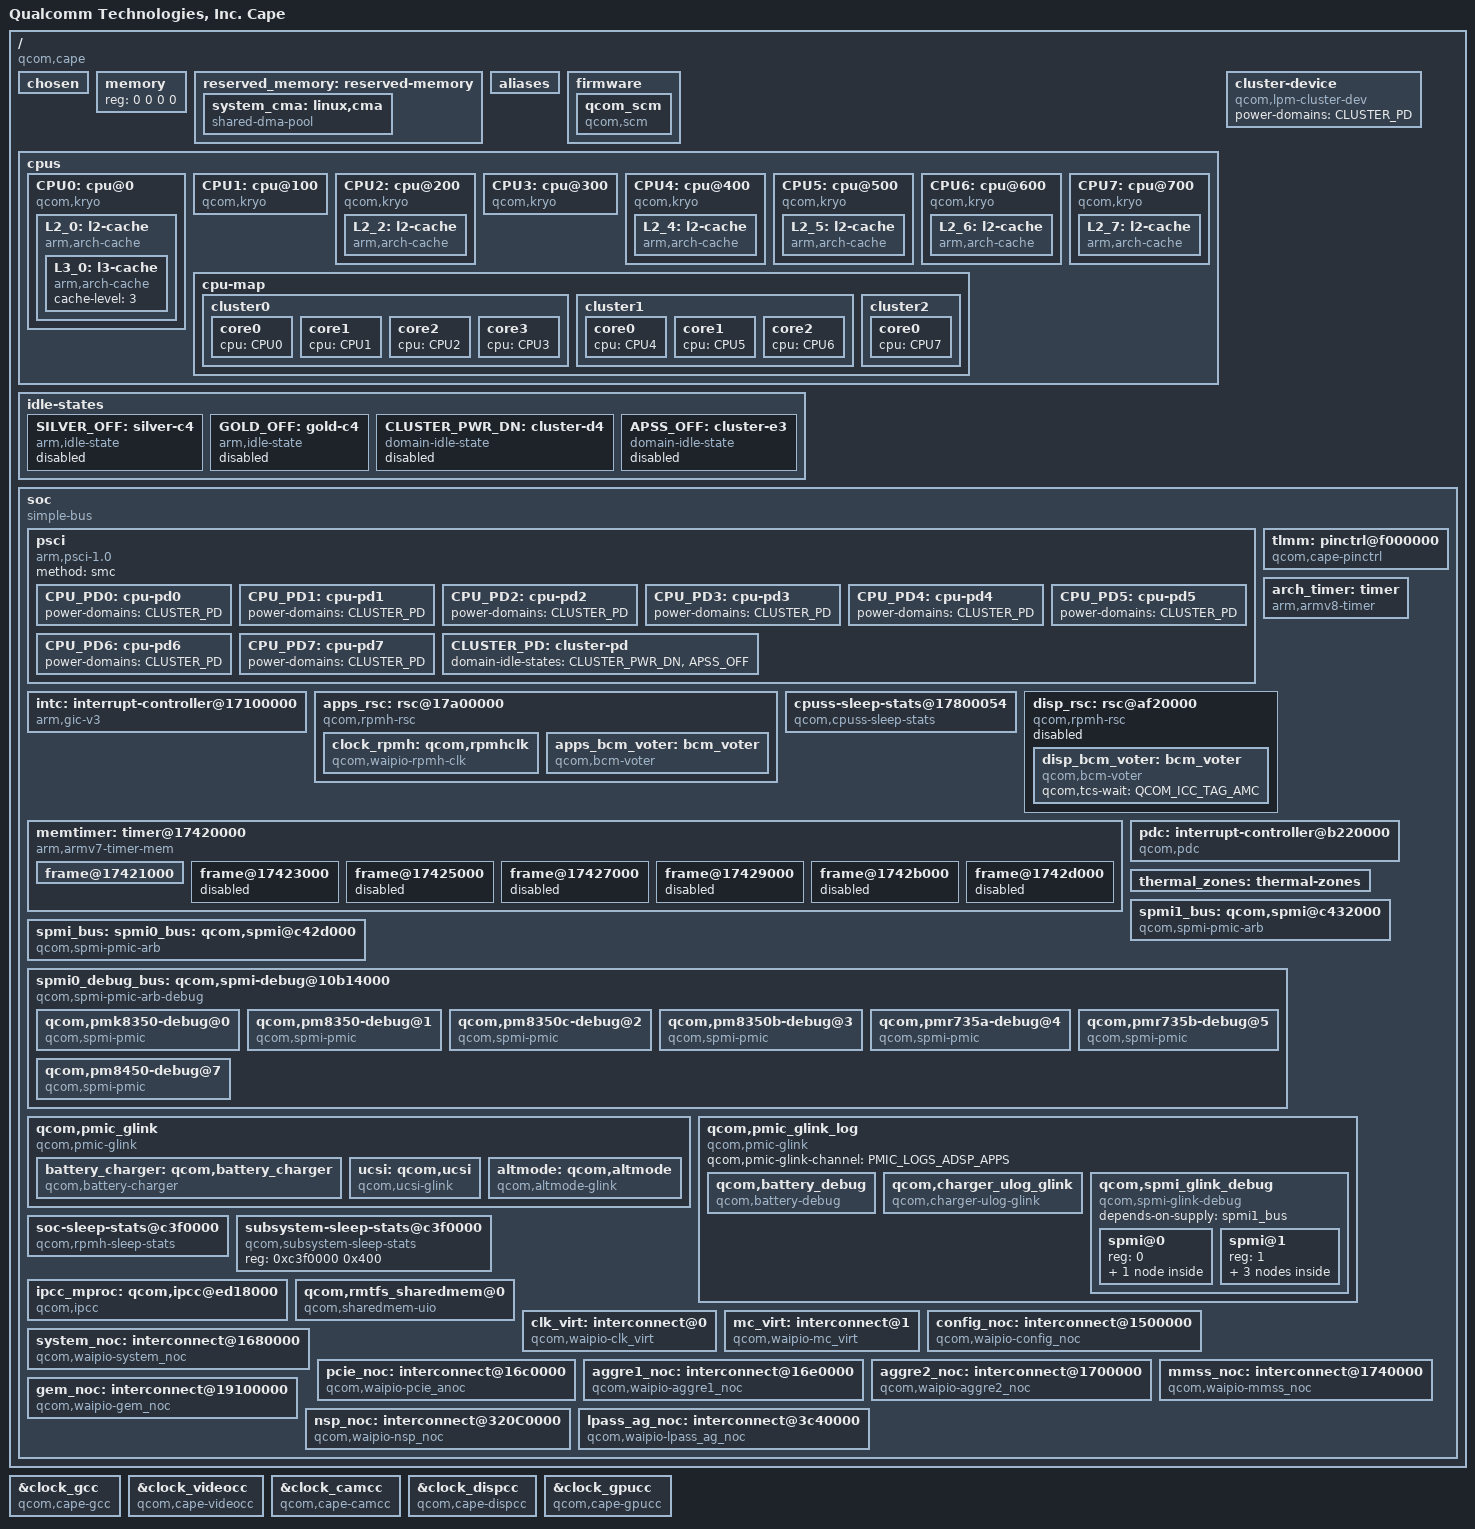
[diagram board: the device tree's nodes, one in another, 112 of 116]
#include <dt-bindings/regulator/qcom,rpmh-regulator-levels.h>
#include <dt-bindings/interconnect/qcom,icc.h>
#include <dt-bindings/interconnect/qcom,waipio.h>
#include <dt-bindings/interrupt-controller/arm-gic.h>
#include <dt-bindings/soc/qcom,rpmh-rsc.h>
#include <dt-bindings/spmi/spmi.h>
/ {
	model = "Qualcomm Technologies, Inc. Cape";
	compatible = "qcom,cape";
	qcom,msm-id = <530 0x10000>;
	interrupt-parent = <&intc>;

	#address-cells = <2>;
	#size-cells = <2>;

	chosen: chosen { };

	memory { device_type = "memory"; reg = <0 0 0 0>; };

	reserved_memory: reserved-memory { };

	aliases { };

	firmware: firmware { };

	cpus {
		#address-cells = <2>;
		#size-cells = <0>;

		CPU0: cpu@0 {
			device_type = "cpu";
			compatible = "qcom,kryo";
			reg = <0x0 0x0>;
			enable-method = "psci";
			next-level-cache = <&L2_0>;
			cpu-idle-states = <&SILVER_OFF>;
			capacity-dmips-mhz = <1024>;
			dynamic-power-coefficient = <100>;
			power-domains = <&CPU_PD0>;
			power-domain-names = "psci";
			L2_0: l2-cache {
			      compatible = "arm,arch-cache";
			      cache-level = <2>;
			      next-level-cache = <&L3_0>;

				L3_0: l3-cache {
					compatible = "arm,arch-cache";
					cache-level = <3>;
				};
			};
		};

		CPU1: cpu@100 {
			device_type = "cpu";
			compatible = "qcom,kryo";
			reg = <0x0 0x100>;
			enable-method = "psci";
			next-level-cache = <&L2_0>; /* silver L2 sharing */
			cpu-idle-states = <&SILVER_OFF>;
			capacity-dmips-mhz = <1024>;
			dynamic-power-coefficient = <100>;
			power-domains = <&CPU_PD1>;
			power-domain-names = "psci";
		};

		CPU2: cpu@200 {
			device_type = "cpu";
			compatible = "qcom,kryo";
			reg = <0x0 0x200>;
			enable-method = "psci";
			next-level-cache = <&L2_2>;
			cpu-idle-states = <&SILVER_OFF>;
			capacity-dmips-mhz = <1024>;
			dynamic-power-coefficient = <100>;
			power-domains = <&CPU_PD2>;
			power-domain-names = "psci";
			L2_2: l2-cache {
			      compatible = "arm,arch-cache";
			      cache-level = <2>;
			      next-level-cache = <&L3_0>;
			};
		};

		CPU3: cpu@300 {
			device_type = "cpu";
			compatible = "qcom,kryo";
			reg = <0x0 0x300>;
			enable-method = "psci";
			next-level-cache = <&L2_2>; /* silver L2 sharing */
			cpu-idle-states = <&SILVER_OFF>;
			capacity-dmips-mhz = <1024>;
			dynamic-power-coefficient = <100>;
			power-domains = <&CPU_PD3>;
			power-domain-names = "psci";
		};

		CPU4: cpu@400 {
			device_type = "cpu";
			compatible = "qcom,kryo";
			reg = <0x0 0x400>;
			enable-method = "psci";
			next-level-cache = <&L2_4>;
			cpu-idle-states = <&GOLD_OFF>;
			capacity-dmips-mhz = <2253>;
			dynamic-power-coefficient = <257>;
			power-domains = <&CPU_PD4>;
			power-domain-names = "psci";
			L2_4: l2-cache {
			      compatible = "arm,arch-cache";
			      cache-level = <2>;
			      next-level-cache = <&L3_0>;
			};
		};

		CPU5: cpu@500 {
			device_type = "cpu";
			compatible = "qcom,kryo";
			reg = <0x0 0x500>;
			enable-method = "psci";
			next-level-cache = <&L2_5>;
			cpu-idle-states = <&GOLD_OFF>;
			capacity-dmips-mhz = <2253>;
			dynamic-power-coefficient = <257>;
			power-domains = <&CPU_PD5>;
			power-domain-names = "psci";
			L2_5: l2-cache {
			      compatible = "arm,arch-cache";
			      cache-level = <2>;
			      next-level-cache = <&L3_0>;
			};
		};

		CPU6: cpu@600 {
			device_type = "cpu";
			compatible = "qcom,kryo";
			reg = <0x0 0x600>;
			enable-method = "psci";
			next-level-cache = <&L2_6>;
			cpu-idle-states = <&GOLD_OFF>;
			capacity-dmips-mhz = <2253>;
			dynamic-power-coefficient = <257>;
			power-domains = <&CPU_PD6>;
			power-domain-names = "psci";
			L2_6: l2-cache {
			      compatible = "arm,arch-cache";
			      cache-level = <2>;
			      next-level-cache = <&L3_0>;
			};
		};

		CPU7: cpu@700 {
			device_type = "cpu";
			compatible = "qcom,kryo";
			reg = <0x0 0x700>;
			enable-method = "psci";
			next-level-cache = <&L2_7>;
			cpu-idle-states = <&GOLD_OFF>;
			capacity-dmips-mhz = <2386>;
			dynamic-power-coefficient = <509>;
			power-domains = <&CPU_PD7>;
			power-domain-names = "psci";
			L2_7: l2-cache {
			      compatible = "arm,arch-cache";
			      cache-level = <2>;
			      next-level-cache = <&L3_0>;
			};
		};

		cpu-map {
			cluster0 {
				core0 {
					cpu = <&CPU0>;
				};

				core1 {
					cpu = <&CPU1>;
				};

				core2 {
					cpu = <&CPU2>;
				};

				core3 {
					cpu = <&CPU3>;
				};
			};

			cluster1 {
				core0 {
					cpu = <&CPU4>;
				};

				core1 {
					cpu = <&CPU5>;
				};

				core2 {
					cpu = <&CPU6>;
				};
			};

			cluster2 {
				core0 {
					cpu = <&CPU7>;
				};
			};
		};
	};

	idle-states {
		SILVER_OFF: silver-c4 {  /* C4 */
			compatible = "arm,idle-state";
			idle-state-name = "rail-pc";
			entry-latency-us = <800>;
			exit-latency-us = <750>;
			min-residency-us = <4090>;
			arm,psci-suspend-param = <0x40000004>;
			local-timer-stop;
			status = "nok";
		};

		GOLD_OFF: gold-c4 {  /* C4 */
			compatible = "arm,idle-state";
			idle-state-name = "rail-pc";
			entry-latency-us = <600>;
			exit-latency-us = <1550>;
			min-residency-us = <4791>;
			arm,psci-suspend-param = <0x40000004>;
			local-timer-stop;
			status = "nok";
		};

		CLUSTER_PWR_DN: cluster-d4 { /* D4 */
			compatible = "domain-idle-state";
			idle-state-name = "l3-off";
			entry-latency-us = <1050>;
			exit-latency-us = <2500>;
			min-residency-us = <5309>;
			arm,psci-suspend-param = <0x41000044>;
			status = "nok";
		};

		APSS_OFF: cluster-e3 { /* E3 */
			compatible = "domain-idle-state";
			idle-state-name = "llcc-off";
			entry-latency-us = <2700>;
			exit-latency-us = <3500>;
			min-residency-us = <13959>;
			arm,psci-suspend-param = <0x4100c344>;
			status = "nok";
		};
	};

	cluster-device {
		compatible = "qcom,lpm-cluster-dev";
		power-domains = <&CLUSTER_PD>;
	};

	soc: soc { };
};

&firmware {
	qcom_scm {
		compatible = "qcom,scm";
	};
};

#include "cape-reserved-memory.dtsi"

&reserved_memory {
	#address-cells = <2>;
	#size-cells = <2>;
	ranges;

	/* global autoconfigured region for contiguous allocations */
	system_cma: linux,cma {
		compatible = "shared-dma-pool";
		alloc-ranges = <0x0 0x00000000 0x0 0xffffffff>;
		reusable;
		alignment = <0x0 0x400000>;
		size = <0x0 0x2000000>;
		linux,cma-default;
	};
};

#include "waipio-clock.dtsi"

&soc {
	#address-cells = <1>;
	#size-cells = <1>;
	ranges = <0 0 0 0xffffffff>;
	compatible = "simple-bus";

	psci {
		compatible = "arm,psci-1.0";
		method = "smc";

		CPU_PD0: cpu-pd0 {
			#power-domain-cells = <0>;
			power-domains = <&CLUSTER_PD>;
		};

		CPU_PD1: cpu-pd1 {
			#power-domain-cells = <0>;
			power-domains = <&CLUSTER_PD>;
		};

		CPU_PD2: cpu-pd2 {
			#power-domain-cells = <0>;
			power-domains = <&CLUSTER_PD>;
		};

		CPU_PD3: cpu-pd3 {
			#power-domain-cells = <0>;
			power-domains = <&CLUSTER_PD>;
		};

		CPU_PD4: cpu-pd4 {
			#power-domain-cells = <0>;
			power-domains = <&CLUSTER_PD>;
		};

		CPU_PD5: cpu-pd5 {
			#power-domain-cells = <0>;
			power-domains = <&CLUSTER_PD>;
		};

		CPU_PD6: cpu-pd6 {
			#power-domain-cells = <0>;
			power-domains = <&CLUSTER_PD>;
		};

		CPU_PD7: cpu-pd7 {
			#power-domain-cells = <0>;
			power-domains = <&CLUSTER_PD>;
		};

		CLUSTER_PD: cluster-pd {
			#power-domain-cells = <0>;
			domain-idle-states = <&CLUSTER_PWR_DN &APSS_OFF>;
		};
	};

	intc: interrupt-controller@17100000 {
		compatible = "arm,gic-v3";
		#interrupt-cells = <3>;
		interrupt-controller;
		#redistributor-regions = <1>;
		redistributor-stride = <0x0 0x40000>;
		reg = <0x17100000 0x10000>,	/* GICD */
		      <0x17180000 0x200000>;	/* GICR * 8 */
		interrupts = <GIC_PPI 9 IRQ_TYPE_LEVEL_LOW>;
	};

	tlmm: pinctrl@f000000 {
		compatible = "qcom,cape-pinctrl";
		reg = <0x0F000000 0x1000000>;
		interrupts = <GIC_SPI 208 IRQ_TYPE_LEVEL_HIGH>;
		gpio-controller;
		#gpio-cells = <2>;
		interrupt-controller;
		#interrupt-cells = <2>;
		wakeup-parent = <&pdc>;
	};

	arch_timer: timer {
		compatible = "arm,armv8-timer";
		interrupts = <GIC_PPI 13 (GIC_CPU_MASK_SIMPLE(8) | IRQ_TYPE_LEVEL_LOW)>,
			     <GIC_PPI 14 (GIC_CPU_MASK_SIMPLE(8) | IRQ_TYPE_LEVEL_LOW)>,
			     <GIC_PPI 11 (GIC_CPU_MASK_SIMPLE(8) | IRQ_TYPE_LEVEL_LOW)>,
			     <GIC_PPI 12 (GIC_CPU_MASK_SIMPLE(8) | IRQ_TYPE_LEVEL_LOW)>;
		clock-frequency = <19200000>;
	};

	apps_rsc: rsc@17a00000 {
		label = "apps_rsc";
		compatible = "qcom,rpmh-rsc";
		reg = <0x17a00000 0x10000>,
		      <0x17a10000 0x10000>,
		      <0x17a20000 0x10000>,
		      <0x17a30000 0x10000>;
		reg-names = "drv-0", "drv-1", "drv-2", "drv-3";
		interrupts = <GIC_SPI 3 IRQ_TYPE_LEVEL_HIGH>,
			     <GIC_SPI 4 IRQ_TYPE_LEVEL_HIGH>,
			     <GIC_SPI 5 IRQ_TYPE_LEVEL_HIGH>;
			     /* No interrupt into GIC for DRV3 */
		qcom,tcs-offset = <0xd00>;
		qcom,drv-id = <2>;
		qcom,tcs-config = <ACTIVE_TCS    3>,
				  <SLEEP_TCS     2>,
				  <WAKE_TCS      2>,
				  <CONTROL_TCS   0>, /* PDC wakeup values will be written from TZ */
				  <FAST_PATH_TCS 1>;
		power-domains = <&CLUSTER_PD>;

		clock_rpmh: qcom,rpmhclk {
			compatible = "qcom,waipio-rpmh-clk";
			#clock-cells = <1>;
		};

		apps_bcm_voter: bcm_voter {
			compatible = "qcom,bcm-voter";
		};
	};

	cpuss-sleep-stats@17800054 {
		compatible = "qcom,cpuss-sleep-stats";
		reg = <0x17800054 0x4>, <0x17810054 0x4>, <0x17820054 0x4>,
		      <0x17830054 0x4>, <0x17840054 0x4>, <0x17850054 0x4>,
		      <0x17860054 0x4>, <0x17870054 0x4>, <0x178A0098 0x4>,
		      <0x178C0000 0x10000>;
		reg-names = "seq_lpm_cntr_cfg_cpu0", "seq_lpm_cntr_cfg_cpu1",
			    "seq_lpm_cntr_cfg_cpu2", "seq_lpm_cntr_cfg_cpu3",
			    "seq_lpm_cntr_cfg_cpu4", "seq_lpm_cntr_cfg_cpu5",
			    "seq_lpm_cntr_cfg_cpu6", "seq_lpm_cntr_cfg_cpu7",
			    "l3_seq_lpm_cntr_cfg", "apss_seq_mem_base";
		num-cpus = <8>;
	};

	disp_rsc: rsc@af20000 {
		label = "disp_rsc";
		compatible = "qcom,rpmh-rsc";
		reg = <0xaf20000 0x10000>;
		reg-names = "drv-0";
		interrupts = <GIC_SPI 129 IRQ_TYPE_LEVEL_HIGH>;
		/* Add clock node here similar to clocks = <&clock_dispcc...> */
		qcom,tcs-offset = <0x1c00>;
		qcom,drv-id = <0>;
		qcom,tcs-config = <ACTIVE_TCS    0>,
				  <SLEEP_TCS     1>,
				  <WAKE_TCS      1>,
				  <CONTROL_TCS   0>,
				  <FAST_PATH_TCS 0>;
		status = "nok"; /* enable once get clock change*/

		disp_bcm_voter: bcm_voter {
			compatible = "qcom,bcm-voter";
			qcom,tcs-wait = <QCOM_ICC_TAG_AMC>;
		};
	};

	memtimer: timer@17420000 {
		#address-cells = <1>;
		#size-cells = <1>;
		ranges;
		compatible = "arm,armv7-timer-mem";
		reg = <0x17420000 0x1000>;
		clock-frequency = <19200000>;

		frame@17421000 {
			frame-number = <0>;
			interrupts = <GIC_SPI 8 IRQ_TYPE_LEVEL_HIGH>,
				     <GIC_SPI 6 IRQ_TYPE_LEVEL_HIGH>;
			reg = <0x17421000 0x1000>,
			      <0x17422000 0x1000>;
		};

		frame@17423000 {
			frame-number = <1>;
			interrupts = <GIC_SPI 9 IRQ_TYPE_LEVEL_HIGH>;
			reg = <0x17423000 0x1000>;
			status = "disabled";
		};

		frame@17425000 {
			frame-number = <2>;
			interrupts = <GIC_SPI 10 IRQ_TYPE_LEVEL_HIGH>;
			reg = <0x17425000 0x1000>;
			status = "disabled";
		};

		frame@17427000 {
			frame-number = <3>;
			interrupts = <GIC_SPI 11 IRQ_TYPE_LEVEL_HIGH>;
			reg = <0x17427000 0x1000>;
			status = "disabled";
		};

		frame@17429000 {
			frame-number = <4>;
			interrupts = <GIC_SPI 12 IRQ_TYPE_LEVEL_HIGH>;
			reg = <0x17429000 0x1000>;
			status = "disabled";
		};

		frame@1742b000 {
			frame-number = <5>;
			interrupts = <GIC_SPI 13 IRQ_TYPE_LEVEL_HIGH>;
			reg = <0x1742b000 0x1000>;
			status = "disabled";
		};

		frame@1742d000 {
			frame-number = <6>;
			interrupts = <GIC_SPI 14 IRQ_TYPE_LEVEL_HIGH>;
			reg = <0x1742d000 0x1000>;
			status = "disabled";
		};
	};

	pdc: interrupt-controller@b220000 {
		compatible = "qcom,pdc", "qcom,cape-pdc";
		reg = <0xb220000 0x30000>, <0x174000f0 0x64>;
		reg-names = "pdc-interrupt-base", "apss-shared-spi-cfg";
		qcom,pdc-ranges = <0 480 94>, <94 609 31>, <125 63 1>,
				  <126 716 12>;
		#interrupt-cells = <2>;
		interrupt-parent = <&intc>;
		interrupt-controller;
	};

	thermal_zones: thermal-zones {
	};

	spmi_bus: spmi0_bus: qcom,spmi@c42d000 {
		compatible = "qcom,spmi-pmic-arb";
		reg = <0xc42d000 0x4000>,
		      <0xc400000 0x3000>,
		      <0xc500000 0x400000>,
		      <0xc440000 0x80000>,
		      <0xc4c0000 0x10000>;
		reg-names = "cnfg", "core", "chnls", "obsrvr", "intr";
		interrupts-extended = <&pdc 1 IRQ_TYPE_LEVEL_HIGH>;
		interrupt-names = "periph_irq";
		interrupt-controller;
		#interrupt-cells = <4>;
		#address-cells = <2>;
		#size-cells = <0>;
		cell-index = <0>;
		qcom,channel = <0>;
		qcom,ee = <0>;
		qcom,bus-id = <0>;
	};

	spmi1_bus: qcom,spmi@c432000 {
		compatible = "qcom,spmi-pmic-arb";
		reg = <0xc432000 0x4000>,
		      <0xc400000 0x3000>,
		      <0xc500000 0x400000>,
		      <0xc440000 0x80000>,
		      <0xc4d0000 0x10000>;
		reg-names = "cnfg", "core", "chnls", "obsrvr", "intr";
		interrupts-extended = <&pdc 3 IRQ_TYPE_LEVEL_HIGH>;
		interrupt-names = "periph_irq";
		interrupt-controller;
		#interrupt-cells = <4>;
		#address-cells = <2>;
		#size-cells = <0>;
		cell-index = <0>;
		qcom,channel = <0>;
		qcom,ee = <0>;
		qcom,bus-id = <1>;
		depends-on-supply = <&spmi0_bus>;
	};

	spmi0_debug_bus: qcom,spmi-debug@10b14000 {
		compatible = "qcom,spmi-pmic-arb-debug";
		reg = <0x10b14000 0x60>, <0x221c8784 0x4>;
		reg-names = "core", "fuse";
		clock-names = "core_clk";
		qcom,fuse-enable-bit = <18>;
		#address-cells = <2>;
		#size-cells = <0>;
		depends-on-supply = <&spmi1_bus>;
		depends-on2-supply = <&smb1394_glink_debug>;

		qcom,pmk8350-debug@0 {
			compatible = "qcom,spmi-pmic";
			reg = <0 SPMI_USID>;
			#address-cells = <2>;
			#size-cells = <0>;
			qcom,can-sleep;
		};

		qcom,pm8350-debug@1 {
			compatible = "qcom,spmi-pmic";
			reg = <1 SPMI_USID>;
			#address-cells = <2>;
			#size-cells = <0>;
			qcom,can-sleep;
		};

		qcom,pm8350c-debug@2 {
			compatible = "qcom,spmi-pmic";
			reg = <2 SPMI_USID>;
			#address-cells = <2>;
			#size-cells = <0>;
			qcom,can-sleep;
		};

		qcom,pm8350b-debug@3 {
			compatible = "qcom,spmi-pmic";
			reg = <3 SPMI_USID>;
			#address-cells = <2>;
			#size-cells = <0>;
			qcom,can-sleep;
		};

		qcom,pmr735a-debug@4 {
			compatible = "qcom,spmi-pmic";
			reg = <4 SPMI_USID>;
			#address-cells = <2>;
			#size-cells = <0>;
			qcom,can-sleep;
		};

		qcom,pmr735b-debug@5 {
			compatible = "qcom,spmi-pmic";
			reg = <5 SPMI_USID>;
			#address-cells = <2>;
			#size-cells = <0>;
			qcom,can-sleep;
		};

		qcom,pm8450-debug@7 {
			compatible = "qcom,spmi-pmic";
			reg = <7 SPMI_USID>;
			#address-cells = <2>;
			#size-cells = <0>;
			qcom,can-sleep;
		};
	};

	qcom,pmic_glink {
		compatible = "qcom,pmic-glink";
		qcom,pmic-glink-channel = "PMIC_RTR_ADSP_APPS";
		qcom,subsys-name = "lpass";
		qcom,protection-domain = "tms/servreg", "msm/adsp/charger_pd";
		depends-on-supply = <&ipcc_mproc>;

		battery_charger: qcom,battery_charger {
			compatible = "qcom,battery-charger";
		};

		ucsi: qcom,ucsi {
			compatible = "qcom,ucsi-glink";
		};

		altmode: qcom,altmode {
			compatible = "qcom,altmode-glink";
			#altmode-cells = <1>;
		};
	};

	qcom,pmic_glink_log {
		compatible = "qcom,pmic-glink";
		qcom,pmic-glink-channel = "PMIC_LOGS_ADSP_APPS";

		qcom,battery_debug {
			compatible = "qcom,battery-debug";
		};

		qcom,charger_ulog_glink {
			compatible = "qcom,charger-ulog-glink";
		};

		qcom,spmi_glink_debug {
			compatible = "qcom,spmi-glink-debug";
			#address-cells = <1>;
			#size-cells = <0>;
			depends-on-supply = <&spmi1_bus>;

			/* Primary SPMI bus */
			spmi@0 {
				reg = <0>;
				#address-cells = <2>;
				#size-cells = <0>;

				qcom,pm8350b-debug@3 {
					compatible = "qcom,spmi-pmic";
					reg = <3 SPMI_USID>;
					qcom,can-sleep;
				};
			};

			/* Secondary SPMI bus */
			spmi@1 {
				reg = <1>;
				#address-cells = <2>;
				#size-cells = <0>;
				smb1394_glink_debug: qcom,smb1394-debug@9 {
					compatible = "qcom,spmi-pmic";
					reg = <9 SPMI_USID>;
					qcom,can-sleep;
				};

				qcom,smb1394-debug@b {
					compatible = "qcom,spmi-pmic";
					reg = <11 SPMI_USID>;
					qcom,can-sleep;
				};

				qcom,smb1396-debug@d {
					compatible = "qcom,spmi-pmic";
					reg = <13 SPMI_USID>;
					qcom,can-sleep;
				};
			};
		};
	};

	soc-sleep-stats@c3f0000 {
		compatible = "qcom,rpmh-sleep-stats";
		reg = <0xc3f0000 0x400>;
		ss-name = "modem", "adsp", "adsp_island",
			  "cdsp", "slpi", "slpi_island",
			  "apss";
	};

	subsystem-sleep-stats@c3f0000 {
		compatible = "qcom,subsystem-sleep-stats";
		reg = <0xc3f0000 0x400>;
	};

	ipcc_mproc: qcom,ipcc@ed18000 {
		compatible = "qcom,ipcc";
		reg = <0xed18000 0x1000>;
		interrupts = <GIC_SPI 229 IRQ_TYPE_LEVEL_HIGH>;
		interrupt-controller;
		#interrupt-cells = <3>;
		#mbox-cells = <2>;
	};

	qcom,rmtfs_sharedmem@0 {
		compatible = "qcom,sharedmem-uio";
		reg = <0x0 0x280000>;
		reg-names = "rmtfs";
		qcom,client-id = <0x00000001>;
	};

	clk_virt: interconnect@0 {
		compatible = "qcom,waipio-clk_virt";
		#interconnect-cells = <1>;
		qcom,bcm-voter-names = "hlos";
		qcom,bcm-voters = <&apps_bcm_voter>;
	};

	mc_virt: interconnect@1 {
		compatible = "qcom,waipio-mc_virt";
		#interconnect-cells = <1>;
		qcom,bcm-voter-names = "hlos", "disp";
		qcom,bcm-voters = <&apps_bcm_voter>, <&disp_bcm_voter>;
	};

	config_noc: interconnect@1500000 {
		reg = <0x1500000 0x1C000>;
		compatible = "qcom,waipio-config_noc";
		#interconnect-cells = <1>;
		qcom,bcm-voter-names = "hlos";
		qcom,bcm-voters = <&apps_bcm_voter>;
	};

	system_noc: interconnect@1680000 {
		reg = <0x1680000 0x1E200>;
		compatible = "qcom,waipio-system_noc";
		#interconnect-cells = <1>;
		qcom,bcm-voter-names = "hlos";
		qcom,bcm-voters = <&apps_bcm_voter>;
	};

	pcie_noc: interconnect@16c0000 {
		reg = <0x16C0000 0xE280>;
		compatible = "qcom,waipio-pcie_anoc";
		#interconnect-cells = <1>;
		qcom,bcm-voter-names = "hlos";
		qcom,bcm-voters = <&apps_bcm_voter>;
	};

	aggre1_noc: interconnect@16e0000 {
		reg = <0x16e0000 0x1C080>;
		compatible = "qcom,waipio-aggre1_noc";
		#interconnect-cells = <1>;
		clocks =
			<&clock_gcc GCC_AGGRE_UFS_PHY_AXI_CLK>,
			<&clock_gcc GCC_AGGRE_USB3_PRIM_AXI_CLK>;
		qcom,bcm-voter-names = "hlos";
		qcom,bcm-voters = <&apps_bcm_voter>;
	};

	aggre2_noc: interconnect@1700000 {
		reg = <0x1700000 0x31080>;
		compatible = "qcom,waipio-aggre2_noc";
		#interconnect-cells = <1>;
		qcom,bcm-voter-names = "hlos";
		qcom,bcm-voters = <&apps_bcm_voter>;
		clocks =
			<&clock_gcc GCC_AGGRE_NOC_PCIE_0_AXI_CLK>,
			<&clock_gcc GCC_AGGRE_NOC_PCIE_1_AXI_CLK>,
			<&clock_gcc GCC_AGGRE_UFS_PHY_AXI_CLK>,
			<&clock_rpmh RPMH_IPA_CLK>;
	};

	mmss_noc: interconnect@1740000 {
		reg = <0x1740000 0x1f080>;
		compatible = "qcom,waipio-mmss_noc";
		#interconnect-cells = <1>;
		qcom,bcm-voter-names = "hlos", "disp";
		qcom,bcm-voters = <&apps_bcm_voter>, <&disp_bcm_voter>;
	};

	gem_noc: interconnect@19100000 {
		reg = <0x19100000 0xBB800>;
		compatible = "qcom,waipio-gem_noc";
		#interconnect-cells = <1>;
		qcom,bcm-voter-names = "hlos", "disp";
		qcom,bcm-voters = <&apps_bcm_voter>, <&disp_bcm_voter>;
	};

	nsp_noc: interconnect@320C0000 {
		reg = <0x320C0000 0x10000>;
		compatible = "qcom,waipio-nsp_noc";
		#interconnect-cells = <1>;
		qcom,bcm-voter-names = "hlos";
		qcom,bcm-voters = <&apps_bcm_voter>;
	};

	lpass_ag_noc: interconnect@3c40000 {
		reg = <0x3c40000 0x17200>;
		compatible = "qcom,waipio-lpass_ag_noc";
		#interconnect-cells = <1>;
		qcom,bcm-voter-names = "hlos";
		qcom,bcm-voters = <&apps_bcm_voter>;
	};
};

&clock_gcc {
	compatible = "qcom,cape-gcc", "syscon";
};

&clock_videocc {
	compatible = "qcom,cape-videocc", "syscon";
};

&clock_camcc {
	compatible = "qcom,cape-camcc", "syscon";
};

&clock_dispcc {
	compatible = "qcom,cape-dispcc", "syscon";
};

&clock_gpucc {
	compatible = "qcom,cape-gpucc", "syscon";
};

#include "cape-pinctrl.dtsi"
#include "cape-regulators.dtsi"
#include "msm-arm-smmu-waipio.dtsi"
